# STM32H7R register map
File version: 1.3
CPU: CM7 r0p1, little endian, MPU, FPU, 4 interrupt priority bits
Registers are 32-bit, read-write, reset 0x0 unless marked. A register's access mark holds for its fields unless they carry their own. Offsets are from the block's base; [hi:lo] are bit positions; {n}, {i} and the like mark numbered series; <NAME> marks a mode.

## SBS — System configuration, boot and security
Base 0x58000400
0x00 BOOTSR ro — SBS boot status register
  [31:0] INITVTOR — initial vector for Cortex-M7 This register includes the physical boot address used by the Cortex-M7 after reset
0x10 HDPLCR reset 0xB4 — SBS hide protection control register
  [7:0] INCR_HDPL — increment HDPL Write 0x6A to increment device HDPL by one. After a write, the register value reverts to its default value (0xB4).
0x14 HDPLSR ro (reset mask 0xFFFFFF00) — SBS hide protection status register
  [7:0] HDPL — hide protection level This bitfield returns the current HDPL of the device. 0x6F and other codes: HDPL3, corresponding to non-boot application. Note: The device state (open/close) is defined in FLASH_NVSTATER register of the embedded Flash memory.
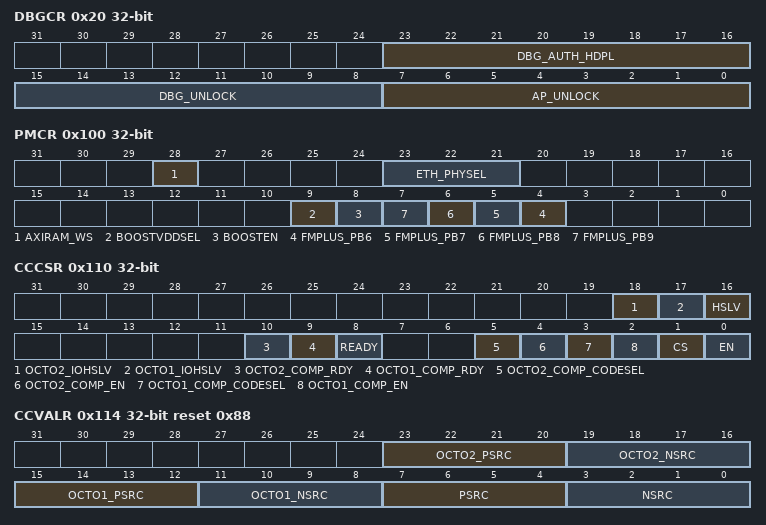
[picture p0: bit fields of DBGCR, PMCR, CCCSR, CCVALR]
0x20 DBGCR — SBS debug control register
  [23:16] DBG_AUTH_HDPL — authenticated debug hide protection level Writing to this bitfield defines at which HDPL the authenticated debug opens. Note: Writing any other values is ignored. Reading any other value means the authenticated debug always fails.
  [15:8] DBG_UNLOCK — debug unlock Write 0xB4 to this bitfield to open the debug when HDPL in SBS_HDPLSR equals to DBG_AUTH_HDPL in this register.
  [7:0] AP_UNLOCK — access port unlock Write 0xB4 to this bitfield to open the device access port.
0x24 DBGLOCKR reset 0xB4 — SBS debug lock register
  [7:0] DBGCFG_LOCK — debug configuration lock Reading this bitfield returns 0x6A if the bitfield value is different from 0xB4. Other: Writes to SBS_DBGCR ignored Note: 0xC3 is the recommended value to lock the debug configuration using this bitfield.
0x34 RSSCMDR — SBS RSS command register
  [15:0] RSSCMD — RSS command The application can use this bitfield to pass on a command to the RSS, executed at the next reset.
0x100 PMCR — SBS product mode and configuration register
  [28] AXIRAM_WS — AXIRAM wait state Set this bit to add one wait state to all AXIRAMs when ECC = 0. When ECC = 1 there is one wait state by default.
  [23:21] ETH_PHYSEL — Ethernet PHY interface selection Other: reserved
  [9] BOOSTVDDSEL — booster V<sub>DD</sub> selection This bit selects the analog switch supply voltage, between V<sub>DD</sub>, V<sub>DDA</sub> and booster. To avoid current consumption due to booster activation when V<sub>DDA</sub> < 2.7 V and V<sub>DD</sub> > 2.7 V, V<sub>DD</sub> can be selected as supply voltage for analog switches. In this case, the BOOSTEN bit must be cleared to avoid unwanted power consumption. When both V<sub>DD and </sub>V<sub>DDA</sub> are below 2.7 V, the booster is still needed to obtain full AC performances from the I/O analog switches.
  [8] BOOSTEN — booster enable Set this bit to reduce the THD of the analog switches when the supply voltage is below 2.7 V. guaranteeing the same performance as with the full voltage range. To avoid current consumption due to booster activation when V<sub>DDA</sub> < 2.7 V and V<sub>DD</sub> > 2.7 V, V<sub>DD</sub> can be selected as supply voltage for analog switches by setting BOOSTVDDSEL bit in SBS_PMCR. In this case, the BOOSTEN bit must be cleared to avoid unwanted power consumption.
  [n-2] FMPLUS_PB{n} (n=6..9) — Fast-mode Plus on PB({n})
0x104 FPUIMR reset 0x1F — SBS FPU interrupt mask register
  [5:0] FPU_IE — FPU interrupt enable Set and cleared by software to enable the Cortex-M7 FPU interrupts xxxxx1: Invalid operation interrupt enabled (xxxxx0 to disable) xxxx1x: Divide-by-zero interrupt enabled (xxxx0x to disable) xxx1xx: Underflow interrupt enabled (xxx0xx to disable) xx1xxx: Overflow interrupt enabled (xx0xxx to disable) x1xxxx: Input denormal interrupt enabled (x0xxxx to disable) 1xxxxx: Inexact interrupt enabled (0xxxxx to disable), disabled by default
0x108 MESR ro — SBS memory erase status register
  [0] MEF — memory erase flag This bit is set by hardware when BKPRAM and PKA SRAM erase is ongoing after a POWER ON reset or one tamper event (see Section 50: Tamper and backup registers (TAMP) for details). This bit is cleared when the erase is done.
0x110 CCCSR access per field — SBS I/O compensation cell control and status register
  [18] OCTO2_IOHSLV rw — XSPIM_P2 I/O high speed at low voltage When this bit is set, the speed of the XSPIM_P2 I/Os is optimized when the device voltage is low. This bit is active only if OCTO2_HSLV user option bit is set in FLASH. This bit must be used only if the device supply voltage is below 2.7 V. Setting this bit when V<sub>DD</sub> is higher than 2.7 V may be destructive.
  [17] OCTO1_IOHSLV rw — XSPIM_P1 I/O high speed at low voltage When this bit is set, the speed of the XSPIM_P1 I/Os is optimized when the device voltage is low. This bit is active only if OCTO1_HSLV user option bit is set in FLASH. This bit must be used only if the device supply voltage is below 2.7 V. Setting this bit when V<sub>DD</sub> is higher than 2.7 V may be destructive.
  [16] HSLV rw — I/O high speed at low voltage When this bit is set, the speed of the I/Os is optimized when the device voltage is low. This bit is active only if VDDIO_HSLV user option bit is set in FLASH. It must be used only if the device supply voltage is below 2.7 V. Setting this bit when V<sub>DD</sub> is higher than 2.7 V may be destructive.
  [10] OCTO2_COMP_RDY ro — XSPIM_P2 compensation cell ready This bit provides the status of the XSPIM_P2 compensation cell.
  [9] OCTO1_COMP_RDY ro — XSPIM_P1 compensation cell ready This bit provides the status of the XSPIM_P1 compensation cell.
  [8] READY ro — Compensation cell ready This bit provides the status of the compensation cell.
  [5] OCTO2_COMP_CODESEL ro — XSPIM_P2 compensation cell code selection This bit selects the code to be applied for the XSPIM_P2 I/O compensation cell.
  [4] OCTO2_COMP_EN ro — XSPIM_P2 compensation cell enable Set this bit to enable the XSPIM_P2 compensation cell.
  [3] OCTO1_COMP_CODESEL rw — XSPIM_P1 compensation cell code selection This bit selects the code to be applied for the XSPIM_P1 I/O compensation cell.
  [2] OCTO1_COMP_EN rw — XSPIM_P1 compensation cell enable Set this bit to enable the XSPIM_P1 compensation cell.
  [1] CS rw — Compensation cell code selection This bit selects the code to be applied for the I/O compensation cell.
  [0] EN rw — Compensation cell enable Set this bit to enable the compensation cell.
0x114 CCVALR ro reset 0x88 — SBS compensation cell for I/Os value register
  [23:20] OCTO2_PSRC — XSPIM_P2 PMOS transistors slew-rate compensation This bitfield returns the PMOS transistors slew-rate compensation value computed by the cell. It is interpreted by XSPIM_P2 to compensate the PMOS transistors slew rate in the functional range if OCTO2_COMP_CODESEL = 0 in SBS_CCCSR register.
  [19:16] OCTO2_NSRC — XSPIM_P2 NMOS transistors slew-rate compensation This bitfield returns the NMOS transistors slew-rate compensation value computed by the cell. It is interpreted by XSPIM_P2 to compensate the NMOS transistors slew rate in the functional range if OCTO2_COMP_CODESEL = 0 in SBS_CCCSR register.
  [15:12] OCTO1_PSRC — XSPIM_P1 PMOS transistors slew-rate compensation This bitfield returns the PMOS transistors slew-rate compensation value computed by the cell. It is interpreted by XSPIM_P1 to compensate the PMOS transistors slew rate in the functional range if OCTO1_COMP_CODESEL = 0 in SBS_CCCSR register.
  [11:8] OCTO1_NSRC — XSPIM_P1 NMOS transistors slew-rate compensation This bitfield returns the NMOS transistors slew-rate compensation value computed by the cell. It is interpreted by XSPIM_P1 to compensate the NMOS transistors slew rate in the functional range if OCTO1_COMP_CODESEL = 0 in SBS_CCCSR register.
  [7:4] PSRC — PMOS transistors slew-rate compensation This bitfield returns the PMOS transistors slew-rate compensation value computed by the cell. It is interpreted to compensate the PMOS transistors slew rate in the functional range if COMP_CODESEL = 0 in SBS_CCCSR register.
  [3:0] NSRC — NMOS transistors slew-rate compensation This bitfield returns the NMOS transistors slew-rate compensation value computed by the cell. It is interpreted to compensate the NMOS transistors slew rate in the functional range if COMP_CODESEL = 0 in SBS_CCCSR register.
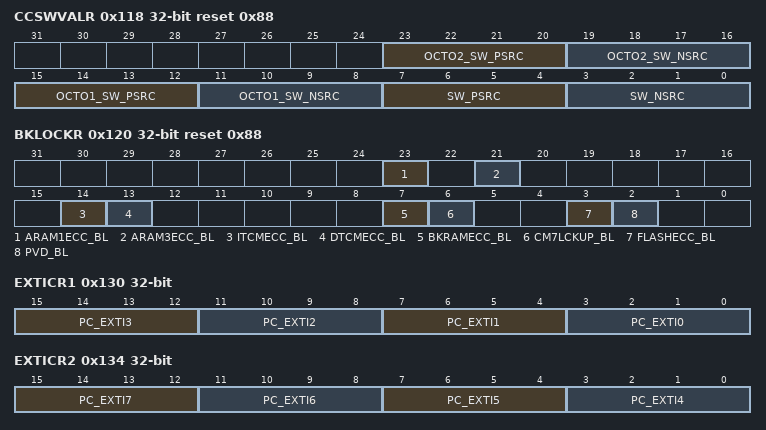
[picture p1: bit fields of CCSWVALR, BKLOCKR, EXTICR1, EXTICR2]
0x118 CCSWVALR reset 0x88 — SBS compensation cell for I/Os software value register
  [23:20] OCTO2_SW_PSRC — XSPIM_P2 software PMOS transistors slew-rate compensation This bitfield returns the PMOS transistors slew-rate compensation value computed by the cell. It is interpreted by XSPIM_P2 to compensate the PMOS transistors slew rate in the functional range if OCTO2_COMP_CODESEL = 1 in SBS_CCCSR register.
  [19:16] OCTO2_SW_NSRC — XSPIM_P2 software NMOS transistors slew-rate compensation This bitfield returns the NMOS transistors slew-rate compensation value computed by the cell. It is interpreted by XSPIM_P2 to compensate the NMOS transistors slew rate in the functional range if OCTO2_COMP_CODESEL = 1 in SBS_CCCSR register.
  [15:12] OCTO1_SW_PSRC — XSPIM_P1 software PMOS transistors slew-rate compensation This bitfield returns the PMOS transistors slew-rate compensation value computed by the cell. It is interpreted by XSPIM_P1 to compensate the PMOS transistors slew rate in the functional range if OCTO1_COMP_CODESEL = 1 in SBS_CCCSR register.
  [11:8] OCTO1_SW_NSRC — XSPIM_P1 software NMOS transistors slew-rate compensation This bitfield returns the NMOS transistors slew -ate compensation value computed by the cell. It is interpreted by XSPIM_P1 to compensate the NMOS transistors slew rate in the functional range if OCTO1_COMP_CODESEL = 1 in SBS_CCCSR register.
  [7:4] SW_PSRC — Software PMOS transistors slew-rate compensation This bitfield returns the PMOS transistors slew-rate compensation value computed by the cell. It is interpreted to compensate the PMOS transistors slew rate in the functional range if COMP_CODESEL = 1 in SBS_CCCSR register.
  [3:0] SW_NSRC — Software NMOS transistors slew-rate compensation This bitfield returns the NMOS transistors slew-rate compensation value computed by the cell. It is interpreted to compensate the NMOS transistors slew rate in the functional range if COMP_CODESEL = 1 in SBS_CCCSR register.
0x120 BKLOCKR reset 0x88 — SBS break lockup register
  [23] ARAM1ECC_BL — AXIRAM1 ECC error break lock Set this bit to enable and lock the connection between AXIRAM1 ECC double error detection flag and break inputs of TIM1/15/16/17 peripherals. Once set, this bit is cleared only by a system reset.
  [21] ARAM3ECC_BL — AXIRAM3 ECC error break lock Set this bit to enable and lock the connection between AXIRAM3 ECC double error detection flag and break inputs of TIM1/15/16/17 peripherals. Once set this bit is cleared only by a system reset.
  [14] ITCMECC_BL — ITCM ECC error break lock Set this bit to enable and lock the connection between ITCM ECC double error detection flag and break inputs of TIM1/15/16/17 peripherals. Once set, this bit is cleared only by a system reset.
  [13] DTCMECC_BL — DTCM ECC error break lock Set this bit to enable and lock the connection between DTCM ECC double error detection flag and break inputs of TIM1/15/16/17 peripherals. Once set, this bit is cleared only by a system reset. Note: The DTCM0 and DTCM1 are Ored to give DTCMECC
  [7] BKRAMECC_BL — Backup RAM ECC error break lock Set this bit to enable and lock the connection between backup RAM ECC double error detection flag and break inputs of TIM1/15/16/17 peripherals. Once set, this bit is cleared only by a system reset.
  [6] CM7LCKUP_BL — Cortex-M7 lockup break lock Set this bit to enable and lock the connection between the Cortex-M7 lockup (HardFault) output and break inputs of TIM1/15/16/17 peripherals. Once set, this bit is cleared only by a system reset.
  [3] FLASHECC_BL — Flash ECC error break lock Set this bit to enable and lock the connection between embedded flash memory ECC double error detection flag and break inputs of TIM1/15/16/17 peripherals. Once set, this bit is cleared only by a system reset.
  [2] PVD_BL — PVD break lock This bit is set by SW and cleared only by a system reset. it can be used to enable and lock the connection to TIM1/8/15/16/17Break input as well as the PVDE and PLS[2:0] bitfields in the PWR_CR1 register. Once set, this bit is cleared only by a system reset.
0x130 EXTICR1 — SBS external interrupt configuration register 0
  [15:12] PC_EXTI3 ro — Port configuration EXTI {0 * 4 + i} This bitfield selects the source input to the EXTI input {0 * 4 + i} used for external interrupt/ event detection. Others: reserved
  [11:8] PC_EXTI2 ro — Port configuration EXTI {0 * 4 + i} This bitfield selects the source input to the EXTI input {0 * 4 + i} used for external interrupt/ event detection. Others: reserved
  [7:4] PC_EXTI1 ro — Port configuration EXTI {0 * 4 + i} This bitfield selects the source input to the EXTI input {0 * 4 + i} used for external interrupt/ event detection. Others: reserved
  [3:0] PC_EXTI0 ro — Port configuration EXTI {0 * 4 + i} This bitfield selects the source input to the EXTI input {0 * 4 + i} used for external interrupt/ event detection. Others: reserved
0x134 EXTICR2 — SBS external interrupt configuration register 1
  [15:12] PC_EXTI7 ro — Port configuration EXTI {1 * 4 + i} This bitfield selects the source input to the EXTI input {1 * 4 + i} used for external interrupt/ event detection. Others: reserved
  [11:8] PC_EXTI6 ro — Port configuration EXTI {1 * 4 + i} This bitfield selects the source input to the EXTI input {1 * 4 + i} used for external interrupt/ event detection. Others: reserved
  [7:4] PC_EXTI5 ro — Port configuration EXTI {1 * 4 + i} This bitfield selects the source input to the EXTI input {1 * 4 + i} used for external interrupt/ event detection. Others: reserved
  [3:0] PC_EXTI4 ro — Port configuration EXTI {1 * 4 + i} This bitfield selects the source input to the EXTI input {1 * 4 + i} used for external interrupt/ event detection. Others: reserved
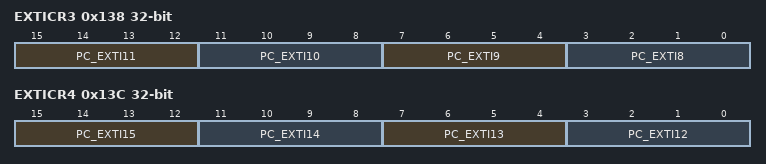
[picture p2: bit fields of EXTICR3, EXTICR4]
0x138 EXTICR3 — SBS external interrupt configuration register 2
  [15:12] PC_EXTI11 ro — Port configuration EXTI {2 * 4 + i} This bitfield selects the source input to the EXTI input {2 * 4 + i} used for external interrupt/ event detection. Others: reserved
  [11:8] PC_EXTI10 ro — Port configuration EXTI {2 * 4 + i} This bitfield selects the source input to the EXTI input {2 * 4 + i} used for external interrupt/ event detection. Others: reserved
  [7:4] PC_EXTI9 ro — Port configuration EXTI {2 * 4 + i} This bitfield selects the source input to the EXTI input {2 * 4 + i} used for external interrupt/ event detection. Others: reserved
  [3:0] PC_EXTI8 ro — Port configuration EXTI {2 * 4 + i} This bitfield selects the source input to the EXTI input {2 * 4 + i} used for external interrupt/ event detection. Others: reserved
0x13C EXTICR4 — SBS external interrupt configuration register 3
  [15:12] PC_EXTI15 ro — Port configuration EXTI {3 * 4 + i} This bitfield selects the source input to the EXTI input {3 * 4 + i} used for external interrupt/ event detection. Others: reserved
  [11:8] PC_EXTI14 ro — Port configuration EXTI {3 * 4 + i} This bitfield selects the source input to the EXTI input {3 * 4 + i} used for external interrupt/ event detection. Others: reserved
  [7:4] PC_EXTI13 ro — Port configuration EXTI {3 * 4 + i} This bitfield selects the source input to the EXTI input {3 * 4 + i} used for external interrupt/ event detection. Others: reserved
  [3:0] PC_EXTI12 ro — Port configuration EXTI {3 * 4 + i} This bitfield selects the source input to the EXTI input {3 * 4 + i} used for external interrupt/ event detection. Others: reserved
